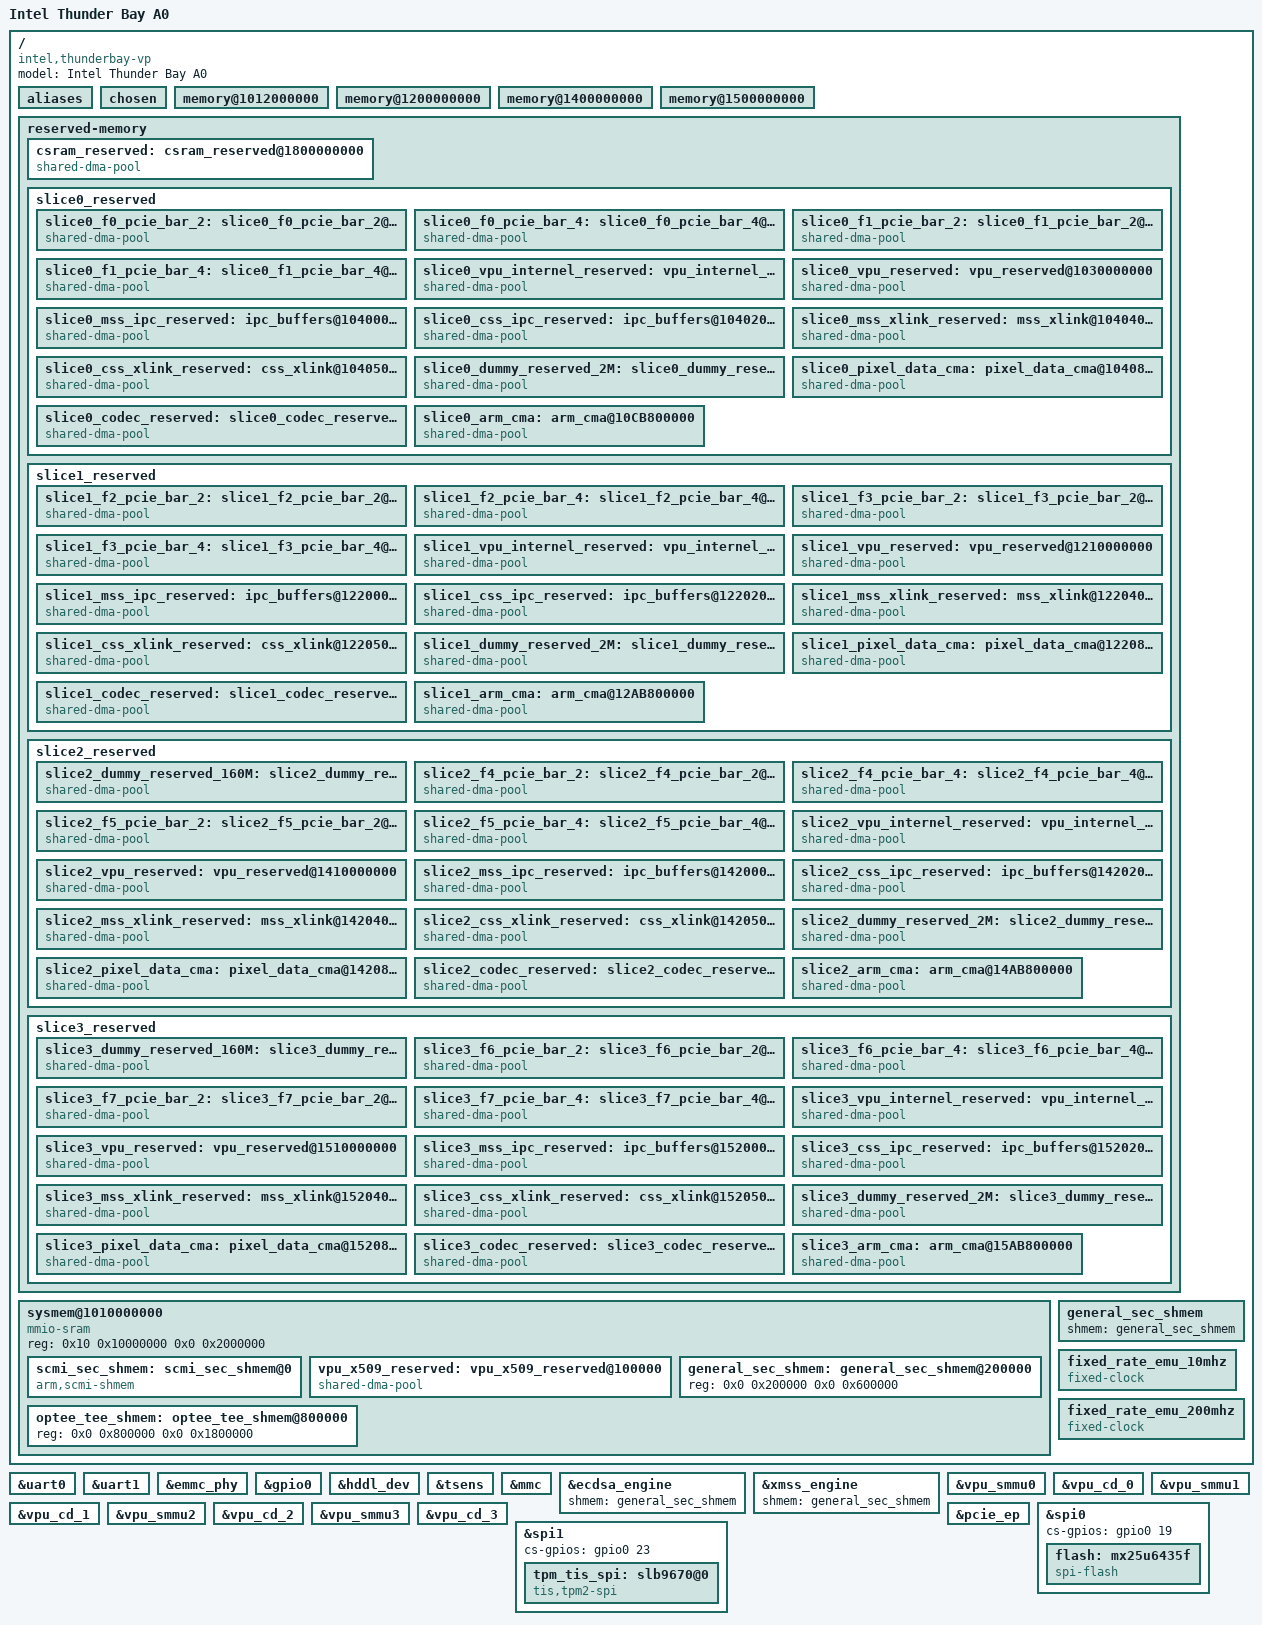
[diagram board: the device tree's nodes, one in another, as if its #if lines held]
/*
 * Device tree describing the Thunder Bay Virtual Platform configuration
 * containing a single Arm core.
 *
 * Copyright (c) 2018 Intel Corporation.
 *
 * SPDX-License-Identifier: GPL-2.0
 *
 */

/dts-v1/;

#include "thb_kernel.dtsi"

/ {
	model = "Intel Thunder Bay A0";
	compatible = "intel,thunderbay-vp";

	#address-cells = <2>;
	#size-cells = <2>;

	aliases {
		serial0 = &uart0;
		serial1 = &uart1;
		spi0 = &spi0;
		spi1 = &spi1;
		gpio0 = &gpio0;
	};

	aliases {
		mmc0 = &mmc;
	};

	chosen {
                //bootargs = "root=/dev/mmcblk0p5 console=uart8250,mmio32,0x80460000,115200n8  initcall_debug rootwait rw rootfstype=ext4";
                bootargs = "mender.data=PARTLABEL=data  root=/dev/mmcblk0p5 console=uart8250,mmio32,0x80460000,115200n8  initcall_debug rootwait rw rootfstype=ext4";
		//bootargs = "root=/dev/mem0      earlycon=uart8250,mmio32,0x80460000,115200n8  initcall_debug rootwait rw rootfstype=ramfs";
		//stdout-path = "serial0:9600n8";
	};

#if ((THB_SLICE_0_EN) || (CRB2_4GB_SLICE_0_SUBMODULE))
	/* 4/8GB of Slice 0 DDR memory */
	memory@1012000000 {
		device_type = "memory";
#if (THB_DDR_CFG_4GB & 0x1)
		reg = <THB_SLICE_0_UPPER32BITS_ADDR 0x12000000 THB_DDR_SLICE0_SIZE_xGB 0xEE000000>;
#else
		reg = <THB_SLICE_0_UPPER32BITS_ADDR 0x12000000 THB_DDR_SLICE0_SIZE_xGB 0xEE000000>;
#endif
	};
#endif

#if ((THB_SLICE_1_EN) || (CRB2_4GB_SLICE_1_SUBMODULE))
	/* 4/8GB of Slice 1 DDR memory */
	memory@1200000000 {
		device_type = "memory";
#if (THB_DDR_CFG_4GB & 0x2)
		reg = <THB_SLICE_1_UPPER32BITS_ADDR SLICE_1_KERNEL_START_ADDR THB_DDR_SLICE1_SIZE_xGB 0x0>;
#else
		reg = <THB_SLICE_1_UPPER32BITS_ADDR SLICE_1_KERNEL_START_ADDR THB_DDR_SLICE1_SIZE_xGB 0x0>;
#endif
	};
#endif

#if (THB_SLICE_2_EN)
	/* 4/8GB of Slice 2 DDR memory */
	memory@1400000000 {
		device_type = "memory";
#if (THB_DDR_CFG_4GB & 0x4)
		reg = <THB_SLICE_2_UPPER32BITS_ADDR 0x0 THB_DDR_SLICE2_SIZE_xGB 0x0>;
#else
		reg = <THB_SLICE_2_UPPER32BITS_ADDR 0x0 THB_DDR_SLICE2_SIZE_xGB 0x0>;
#endif
	};
#endif

#if (THB_SLICE_3_EN)
	/* 4/8GB of Slice 3 DDR memory */
	memory@1500000000 {
		device_type = "memory";
#if (THB_DDR_CFG_4GB & 0x8)
		reg = <THB_SLICE_3_UPPER32BITS_ADDR 0x0 THB_DDR_SLICE3_SIZE_xGB 0x0>;
#else
		reg = <THB_SLICE_3_UPPER32BITS_ADDR 0x0 THB_DDR_SLICE3_SIZE_xGB 0x0>;
#endif
	};
#endif

	reserved-memory {
		#address-cells = <2>;
		#size-cells = <2>;
		ranges;

		csram_reserved: csram_reserved@1800000000 {
			compatible = "shared-dma-pool";
			reg = <0x18 0x00000000 0x0 0x01800000>;
			no-map;
		};

#if (THB_SLICE_0_EN)
		slice0_reserved {
			#address-cells = <2>;
			#size-cells = <2>;
			ranges;

			slice0_f0_pcie_bar_2: slice0_f0_pcie_bar_2@102A000000 {
				compatible = "shared-dma-pool";
				reg = <THB_SLICE_0_UPPER32BITS_ADDR 0x2A000000 0x00 0x1000000>; /* 16MB */
				no-map;
			};

			slice0_f0_pcie_bar_4: slice0_f0_pcie_bar_4@102B000000 {
				compatible = "shared-dma-pool";
				reg = <THB_SLICE_0_UPPER32BITS_ADDR 0x2B000000 0x00 0x800000>; /* 8MB */
				no-map;
			};

			slice0_f1_pcie_bar_2: slice0_f1_pcie_bar_2@102B800000 {
				compatible = "shared-dma-pool";
				reg = <THB_SLICE_0_UPPER32BITS_ADDR 0x2B800000 0x00 0x1000000>; /* 16MB */
				no-map;
			};

			slice0_f1_pcie_bar_4: slice0_f1_pcie_bar_4@102C800000 {
				compatible = "shared-dma-pool";
				reg = <THB_SLICE_0_UPPER32BITS_ADDR 0x2C800000 0x00 0x800000>; /* 8MB */
				no-map;
			};

			/* Reserved for VPU */
			slice0_vpu_internel_reserved: vpu_internel_reserved@102D000000 {
				compatible = "shared-dma-pool";
				reg = <THB_SLICE_0_UPPER32BITS_ADDR 0x2D000000 0x0 0x3000000>; /* 48MB */
				no-map;
			};

			/* Allocate 256MB at fixed location for VPU */
			slice0_vpu_reserved: vpu_reserved@1030000000 {
				compatible = "shared-dma-pool";
				reg = <THB_SLICE_0_UPPER32BITS_ADDR 0x30000000 0x0 0x10000000>; /* 256MB */
				no-map;
			};

			/* Allocate 2MB at fixed location for MSS IPC */
			slice0_mss_ipc_reserved: ipc_buffers@1040000000 {
				compatible = "shared-dma-pool";
				reg = <THB_SLICE_0_UPPER32BITS_ADDR 0x40000000 0x0 0x200000>; /* 2MB */
				no-map;
			};

			/* Allocate 2MB at fixed location for CSS IPC */
			slice0_css_ipc_reserved: ipc_buffers@1040200000 {
				compatible = "shared-dma-pool";
				reg = <THB_SLICE_0_UPPER32BITS_ADDR 0x40200000 0x0 0x200000>; /* 2MB */
				no-map;
			};

			slice0_mss_xlink_reserved: mss_xlink@1040400000 {
				compatible = "shared-dma-pool";
				reg = <THB_SLICE_0_UPPER32BITS_ADDR 0x40400000 0x0 0x00100000>; /* 1MB */
				no-map;
			};

			slice0_css_xlink_reserved: css_xlink@1040500000 {
				compatible = "shared-dma-pool";
				reg = <THB_SLICE_0_UPPER32BITS_ADDR 0x40500000 0x0 0x00100000>; /* 1MB */
				no-map;
			};

			/* Free 2 MB dummy section */
			slice0_dummy_reserved_2M: slice0_dummy_reserved_2M@1040600000 {
				compatible = "shared-dma-pool";
				reg = <THB_SLICE_0_UPPER32BITS_ADDR 0x40600000 0x0 0x200000>; /* 2MB */
				no-map;
			};

			slice0_pixel_data_cma: pixel_data_cma@1040800000 {
				compatible = "shared-dma-pool";
				reg = <THB_SLICE_0_UPPER32BITS_ADDR 0x40800000 0x0 0x6B000000>; /* 1712MB */
				reusable;
			};

			slice0_codec_reserved: slice0_codec_reserved@10AB800000 {
				compatible = "shared-dma-pool";
				reg = <THB_SLICE_0_UPPER32BITS_ADDR 0xAB800000 0x00 0x20000000>; /* 512MB */
				no-map;
			};

			slice0_arm_cma: arm_cma@10CB800000 {
				compatible = "shared-dma-pool";
				reg = <THB_SLICE_0_UPPER32BITS_ADDR 0xCB800000 0x0 0xC000000>; /* 192MB */
				reusable;
			};
		};
#endif

#if (THB_SLICE_1_EN)
		slice1_reserved {
			#address-cells = <2>;
			#size-cells = <2>;
			ranges;
#if (THB_SEC_SLICE)

			slice1_f2_pcie_bar_2: slice1_f2_pcie_bar_2@120A000000 {
				compatible = "shared-dma-pool";
				reg = <THB_SLICE_1_UPPER32BITS_ADDR 0x2A000000 0x00 0x1000000>; /* 16MB */
				no-map;
			};

			slice1_f2_pcie_bar_4: slice1_f2_pcie_bar_4@120B000000 {
				compatible = "shared-dma-pool";
				reg = <THB_SLICE_1_UPPER32BITS_ADDR 0x2B000000 0x00 0x800000>; /* 8MB */
				no-map;
			};

			slice1_f3_pcie_bar_2: slice1_f3_pcie_bar_2@120B800000 {
				compatible = "shared-dma-pool";
				reg = <THB_SLICE_1_UPPER32BITS_ADDR 0x2B800000 0x00 0x1000000>; /* 16MB */
				no-map;
			};

			slice1_f3_pcie_bar_4: slice1_f3_pcie_bar_4@120C800000 {
				compatible = "shared-dma-pool";
				reg = <THB_SLICE_1_UPPER32BITS_ADDR 0x2C800000 0x00 0x800000>; /* 8MB */
				no-map;
			};

			/* Reserved for VPU */
			slice1_vpu_internel_reserved: vpu_internel_reserved@120D000000 {
				compatible = "shared-dma-pool";
				reg = <THB_SLICE_1_UPPER32BITS_ADDR 0x2D000000 0x0 0x3000000>; /* 48MB */
				no-map;
			};

			/* Allocate 256MB at fixed location for VPU */
			slice1_vpu_reserved: vpu_reserved@1210000000 {
				compatible = "shared-dma-pool";
				reg = <THB_SLICE_1_UPPER32BITS_ADDR 0x30000000 0x0 0x10000000>; /* 256MB */
				no-map;
			};

			/* Allocate 2MB at fixed location for MSS IPC */
			slice1_mss_ipc_reserved: ipc_buffers@1220000000 {
				compatible = "shared-dma-pool";
				reg = <THB_SLICE_1_UPPER32BITS_ADDR 0x40000000 0x0 0x200000>; /* 2MB */
				no-map;
			};

			/* Allocate 2MB at fixed location for CSS IPC */
			slice1_css_ipc_reserved: ipc_buffers@1220200000 {
				compatible = "shared-dma-pool";
				reg = <THB_SLICE_1_UPPER32BITS_ADDR 0x40200000 0x0 0x200000>; /* 2MB */
				no-map;
			};

			slice1_mss_xlink_reserved: mss_xlink@1220400000 {
				compatible = "shared-dma-pool";
				reg = <THB_SLICE_1_UPPER32BITS_ADDR 0x40400000 0x0 0x00100000>; /* 1MB */
				no-map;
			};

			slice1_css_xlink_reserved: css_xlink@1220500000 {
				compatible = "shared-dma-pool";
				reg = <THB_SLICE_1_UPPER32BITS_ADDR 0x40500000 0x0 0x00100000>; /* 1MB */
				no-map;
			};

			/* Free 2 MB dummy section */
			slice1_dummy_reserved_2M: slice1_dummy_reserved_2M@1220600000 {
				compatible = "shared-dma-pool";
				reg = <THB_SLICE_1_UPPER32BITS_ADDR 0x40600000 0x0 0x200000>; /* 2MB */
				no-map;
			};

			slice1_pixel_data_cma: pixel_data_cma@1220800000 {
				compatible = "shared-dma-pool";
				reg = <THB_SLICE_1_UPPER32BITS_ADDR 0x40800000 0x0 0x6B000000>; /* 1712MB */
				reusable;
			};

			slice1_codec_reserved: slice1_codec_reserved@128B800000 {
				compatible = "shared-dma-pool";
				reg = <THB_SLICE_1_UPPER32BITS_ADDR 0xAB800000 0x00 0x20000000>; /* 512MB */
				no-map;
			};

			slice1_arm_cma: arm_cma@12AB800000 {
				compatible = "shared-dma-pool";
				reg = <THB_SLICE_1_UPPER32BITS_ADDR 0xCB800000 0x0 0xC000000>; /* 192MB */
				reusable;
			};
#else
			/* Free 160 MB dummy section */
			slice1_dummy_reserved_160M: slice1_dummy_reserved_160M@1200000000 {
				compatible = "shared-dma-pool";
				reg = <THB_SLICE_1_UPPER32BITS_ADDR 0x00000000 0x0 0xA000000>; /* 160MB */
				no-map;
			};

			slice1_f2_pcie_bar_2: slice1_f2_pcie_bar_2@120A000000 {
				compatible = "shared-dma-pool";
				reg = <THB_SLICE_1_UPPER32BITS_ADDR 0x0A000000 0x00 0x1000000>; /* 16MB */
				no-map;
			};

			slice1_f2_pcie_bar_4: slice1_f2_pcie_bar_4@120B000000 {
				compatible = "shared-dma-pool";
				reg = <THB_SLICE_1_UPPER32BITS_ADDR 0x0B000000 0x00 0x800000>; /* 8MB */
				no-map;
			};

			slice1_f3_pcie_bar_2: slice1_f3_pcie_bar_2@120B800000 {
				compatible = "shared-dma-pool";
				reg = <THB_SLICE_1_UPPER32BITS_ADDR 0x0B800000 0x00 0x1000000>; /* 16MB */
				no-map;
			};

			slice1_f3_pcie_bar_4: slice1_f3_pcie_bar_4@120C800000 {
				compatible = "shared-dma-pool";
				reg = <THB_SLICE_1_UPPER32BITS_ADDR 0x0C800000 0x00 0x800000>; /* 8MB */
				no-map;
			};

			/* Reserved for VPU */
			slice1_vpu_internel_reserved: vpu_internel_reserved@120D000000 {
				compatible = "shared-dma-pool";
				reg = <THB_SLICE_1_UPPER32BITS_ADDR 0x0D000000 0x0 0x3000000>; /* 48MB */
				no-map;
			};

			/* Allocate 256MB at fixed location for VPU */
			slice1_vpu_reserved: vpu_reserved@1210000000 {
				compatible = "shared-dma-pool";
				reg = <THB_SLICE_1_UPPER32BITS_ADDR 0x10000000 0x0 0x10000000>; /* 256MB */
				no-map;
			};

			/* Allocate 2MB at fixed location for MSS IPC */
			slice1_mss_ipc_reserved: ipc_buffers@1220000000 {
				compatible = "shared-dma-pool";
				reg = <THB_SLICE_1_UPPER32BITS_ADDR 0x20000000 0x0 0x200000>; /* 2MB */
				no-map;
			};

			/* Allocate 2MB at fixed location for CSS IPC */
			slice1_css_ipc_reserved: ipc_buffers@1220200000 {
				compatible = "shared-dma-pool";
				reg = <THB_SLICE_1_UPPER32BITS_ADDR 0x20200000 0x0 0x200000>; /* 2MB */
				no-map;
			};

			slice1_mss_xlink_reserved: mss_xlink@1220400000 {
				compatible = "shared-dma-pool";
				reg = <THB_SLICE_1_UPPER32BITS_ADDR 0x20400000 0x0 0x00100000>; /* 1MB */
				no-map;
			};

			slice1_css_xlink_reserved: css_xlink@1220500000 {
				compatible = "shared-dma-pool";
				reg = <THB_SLICE_1_UPPER32BITS_ADDR 0x20500000 0x0 0x00100000>; /* 1MB */
				no-map;
			};

			/* Free 2 MB dummy section */
			slice1_dummy_reserved_2M: slice1_dummy_reserved_2M@1220600000 {
				compatible = "shared-dma-pool";
				reg = <THB_SLICE_1_UPPER32BITS_ADDR 0x20600000 0x0 0x00200000>; /* 2MB */
				no-map;
			};

			slice1_pixel_data_cma: pixel_data_cma@1220800000 {
				compatible = "shared-dma-pool";
				reg = <THB_SLICE_1_UPPER32BITS_ADDR 0x20800000 0x0 0x6B000000>; /* 1712MB */
				reusable;
			};

			slice1_codec_reserved: slice1_codec_reserved@128B800000 {
				compatible = "shared-dma-pool";
				reg = <THB_SLICE_1_UPPER32BITS_ADDR 0x8B800000 0x00 0x20000000>; /* 512MB */
				no-map;
			};

			slice1_arm_cma: arm_cma@12AB800000 {
				compatible = "shared-dma-pool";
				reg = <THB_SLICE_1_UPPER32BITS_ADDR 0xAB800000 0x0 0xC000000>; /* 192MB */
				reusable;
			};
#endif
		};
#endif

#if (THB_SLICE_2_EN)
		slice2_reserved {
		#address-cells = <2>;
		#size-cells = <2>;
		ranges;

			/* Free 160 MB dummy section */
			slice2_dummy_reserved_160M: slice2_dummy_reserved_160M@1400000000 {
				compatible = "shared-dma-pool";
				reg = <THB_SLICE_2_UPPER32BITS_ADDR 0x00000000 0x0 0xA000000>; /* 160MB */
				no-map;
			};

			slice2_f4_pcie_bar_2: slice2_f4_pcie_bar_2@140A000000 {
				compatible = "shared-dma-pool";
				reg = <THB_SLICE_2_UPPER32BITS_ADDR 0x0A000000 0x00 0x1000000>; /* 16MB */
				no-map;
			};

			slice2_f4_pcie_bar_4: slice2_f4_pcie_bar_4@140B000000 {
				compatible = "shared-dma-pool";
				reg = <THB_SLICE_2_UPPER32BITS_ADDR 0x0B000000 0x00 0x800000>; /* 8MB */
				no-map;
			};

			slice2_f5_pcie_bar_2: slice2_f5_pcie_bar_2@140B800000 {
				compatible = "shared-dma-pool";
				reg = <THB_SLICE_2_UPPER32BITS_ADDR 0x0B800000 0x00 0x1000000>; /* 16MB */
				no-map;
			};

			slice2_f5_pcie_bar_4: slice2_f5_pcie_bar_4@140C800000 {
				compatible = "shared-dma-pool";
				reg = <THB_SLICE_2_UPPER32BITS_ADDR 0x0C800000 0x00 0x800000>; /* 8MB */
				no-map;
			};

			/* Reserved for VPU */
			slice2_vpu_internel_reserved: vpu_internel_reserved@140D000000 {
				compatible = "shared-dma-pool";
				reg = <THB_SLICE_2_UPPER32BITS_ADDR 0x0D000000 0x0 0x3000000>; /* 48MB */
				no-map;
			};

			/* Allocate 256MB at fixed location for VPU */
			slice2_vpu_reserved: vpu_reserved@1410000000 {
				compatible = "shared-dma-pool";
				reg = <THB_SLICE_2_UPPER32BITS_ADDR 0x10000000 0x0 0x10000000>; /* 256MB */
				no-map;
			};

			/* Allocate 2MB at fixed location for MSS IPC */
			slice2_mss_ipc_reserved: ipc_buffers@1420000000 {
				compatible = "shared-dma-pool";
				reg = <THB_SLICE_2_UPPER32BITS_ADDR 0x20000000 0x0 0x200000>; /* 2MB */
				no-map;
			};

			/* Allocate 2MB at fixed location for CSS IPC */
			slice2_css_ipc_reserved: ipc_buffers@1420200000 {
				compatible = "shared-dma-pool";
				reg = <THB_SLICE_2_UPPER32BITS_ADDR 0x20200000 0x0 0x200000>; /* 2MB */
				no-map;
			};

			slice2_mss_xlink_reserved: mss_xlink@1420400000 {
				compatible = "shared-dma-pool";
				reg = <THB_SLICE_2_UPPER32BITS_ADDR 0x20400000 0x0 0x00100000>; /* 1MB */
				no-map;
			};

			slice2_css_xlink_reserved: css_xlink@1420500000 {
				compatible = "shared-dma-pool";
				reg = <THB_SLICE_2_UPPER32BITS_ADDR 0x20500000 0x0 0x00100000>; /* 1MB */
				no-map;
			};

			/* Free 2 MB dummy section */
			slice2_dummy_reserved_2M: slice2_dummy_reserved_2M@1420600000 {
				compatible = "shared-dma-pool";
				reg = <THB_SLICE_2_UPPER32BITS_ADDR 0x20600000 0x0 0x00200000>; /* 2MB */
				no-map;
			};

			slice2_pixel_data_cma: pixel_data_cma@1420800000 {
				compatible = "shared-dma-pool";
				reg = <THB_SLICE_2_UPPER32BITS_ADDR 0x20800000 0x0 0x6B000000>; /* 1712MB */
				reusable;
			};

			slice2_codec_reserved: slice2_codec_reserved@148B800000 {
				compatible = "shared-dma-pool";
				reg = <THB_SLICE_2_UPPER32BITS_ADDR 0x8B800000 0x00 0x20000000>; /* 512MB */
				no-map;
			};

			slice2_arm_cma: arm_cma@14AB800000 {
				compatible = "shared-dma-pool";
				reg = <THB_SLICE_2_UPPER32BITS_ADDR 0xAB800000 0x0 0xC000000>; /* 192MB */
				reusable;
			};
		};
#endif

#if (THB_SLICE_3_EN)
		slice3_reserved {
			#address-cells = <2>;
			#size-cells = <2>;
			ranges;

			/* Free 160 MB dummy section */
			slice3_dummy_reserved_160M: slice3_dummy_reserved_160M@1500000000 {
				compatible = "shared-dma-pool";
				reg = <THB_SLICE_3_UPPER32BITS_ADDR 0x00000000 0x0 0xA000000>; /* 160MB */
				no-map;
			};

			slice3_f6_pcie_bar_2: slice3_f6_pcie_bar_2@150A000000 {
				compatible = "shared-dma-pool";
				reg = <THB_SLICE_3_UPPER32BITS_ADDR 0x0A000000 0x00 0x1000000>; /* 16MB */
				no-map;
			};

			slice3_f6_pcie_bar_4: slice3_f6_pcie_bar_4@150B000000 {
				compatible = "shared-dma-pool";
				reg = <THB_SLICE_3_UPPER32BITS_ADDR 0x0B000000 0x00 0x800000>; /* 8MB */
				no-map;
			};

			slice3_f7_pcie_bar_2: slice3_f7_pcie_bar_2@150B800000 {
				compatible = "shared-dma-pool";
				reg = <THB_SLICE_3_UPPER32BITS_ADDR 0x0B800000 0x00 0x1000000>; /* 16MB */
				no-map;
			};

			slice3_f7_pcie_bar_4: slice3_f7_pcie_bar_4@150C800000 {
				compatible = "shared-dma-pool";
				reg = <THB_SLICE_3_UPPER32BITS_ADDR 0x0C800000 0x00 0x800000>; /* 8MB */
				no-map;
			};

			/* Reserved for VPU */
			slice3_vpu_internel_reserved: vpu_internel_reserved@150D000000 {
				compatible = "shared-dma-pool";
				reg = <THB_SLICE_3_UPPER32BITS_ADDR 0x0D000000 0x0 0x3000000>; /* 48MB */
				no-map;
			};

			/* Allocate 256MB at fixed location for VPU */
			slice3_vpu_reserved: vpu_reserved@1510000000 {
				compatible = "shared-dma-pool";
				reg = <THB_SLICE_3_UPPER32BITS_ADDR 0x10000000 0x0 0x10000000>; /* 256MB */
				no-map;
			};

			/* Allocate 2MB at fixed location for MSS IPC */
			slice3_mss_ipc_reserved: ipc_buffers@1520000000 {
				compatible = "shared-dma-pool";
				reg = <THB_SLICE_3_UPPER32BITS_ADDR 0x20000000 0x0 0x200000>; /* 2MB */
				no-map;
			};

			/* Allocate 2MB at fixed location for CSS IPC */
			slice3_css_ipc_reserved: ipc_buffers@1520200000 {
				compatible = "shared-dma-pool";
				reg = <THB_SLICE_3_UPPER32BITS_ADDR 0x20200000 0x0 0x200000>; /* 2MB */
				no-map;
			};

			slice3_mss_xlink_reserved: mss_xlink@1520400000 {
				compatible = "shared-dma-pool";
				reg = <THB_SLICE_3_UPPER32BITS_ADDR 0x20400000 0x0 0x00100000>; /* 1MB */
				no-map;
			};

			slice3_css_xlink_reserved: css_xlink@1520500000 {
				compatible = "shared-dma-pool";
				reg = <THB_SLICE_3_UPPER32BITS_ADDR 0x20500000 0x0 0x00100000>; /* 1MB */
				no-map;
			};

			/* Free 2 MB dummy section */
			slice3_dummy_reserved_2M: slice3_dummy_reserved_2M@1520600000 {
				compatible = "shared-dma-pool";
				reg = <THB_SLICE_3_UPPER32BITS_ADDR 0x20600000 0x0 0x00200000>; /* 2MB */
				no-map;
			};

			slice3_pixel_data_cma: pixel_data_cma@1520800000 {
				compatible = "shared-dma-pool";
				reg = <THB_SLICE_3_UPPER32BITS_ADDR 0x20800000 0x0 0x6B000000>; /* 1712MB */
				reusable;
			};

			slice3_codec_reserved: slice3_codec_reserved@158B800000 {
				compatible = "shared-dma-pool";
				reg = <THB_SLICE_3_UPPER32BITS_ADDR 0x8B800000 0x00 0x20000000>; /* 512MB */
				no-map;
			};

			slice3_arm_cma: arm_cma@15AB800000 {
				compatible = "shared-dma-pool";
				reg = <THB_SLICE_3_UPPER32BITS_ADDR 0xAB800000 0x0 0xC000000>; /* 192MB */
				reusable;
			};
		};
#endif
	};

	sysmem@1010000000 {
		compatible = "mmio-sram";
		#address-cells = <2>;
		#size-cells = <2>;
		reg = <0x10 0x10000000 0x0 0x2000000>;
		ranges = <0 0x0  0x10 0x10000000 0x0 0x2000000>;

		/*
		* Allocate 1MB at fixed location for shared memory between
		* non-secure world and BL31 to be used for SCMI.
		*/
		scmi_sec_shmem: scmi_sec_shmem@0 {
			compatible = "arm,scmi-shmem";
			reg = <0x0 0x0 0x0 0x100000>;
			pool;
		};

		/*
		* Allocate some space in shared area for VPU IPC driver
		* to place the X509 certificate.
		*/
		vpu_x509_reserved: vpu_x509_reserved@100000 {
			compatible = "shared-dma-pool";
			reg = <0x0 0x100000 0x0 0x100000>;
			no-map;
		};

		/* Allocate the rest of shared memory for general use.
		 * VPU x509 certificate area will occupy/allocated
		 * from the below region by the IPC driver. So, optee
		 * needs to know the region for the VPU authentication
		 * service TA. https://hsdes.intel.com/resource/16011061170
		 */
		general_sec_shmem: general_sec_shmem@200000 {
			reg = <0x0 0x200000 0x0 0x600000>;
		};

		optee_tee_shmem: optee_tee_shmem@800000 {
                       reg = <0x0 0x800000 0x0 0x1800000>;
               };
	};

	/*
	* For U-Boot to reference the general use shared memory
	* area, we use this node.
	*/
	general_sec_shmem {
		shmem = <&general_sec_shmem>;
	};

	fixed_rate_emu_10mhz: fixed_rate_emu_10mhz {
		compatible = "fixed-clock";
		#clock-cells = <0>;
		clock-frequency = <50000000>;
		clock-output-names = "dummy_clk";
		u-boot,dm-pre-reloc;
	};

	fixed_rate_emu_200mhz: fixed_rate_emu_200mhz {
		compatible = "fixed-clock";
		#clock-cells = <0>;
		clock-frequency = <25000000>;
		clock-output-names = "dummy1_clk";
		u-boot,dm-pre-reloc;
	};
};

&uart0 {
	status = "okay";
};

&uart1 {
	status = "okay";
};

&emmc_phy {
	status = "okay";
	//clocks = <&fixed_rate_emu_200mhz>;
	//clocks = <&scmi_clk PSS_CPR_CPR_CLK>;
};

&gpio0 {
       status = "okay";
};

&hddl_dev {
       status = "okay";
};

&tsens {
       status = "okay";
};

&mmc {
	status = "okay";
	//clocks = <&fixed_rate_emu_200mhz>, <&fixed_rate_emu_200mhz>;
	//clocks = <&scmi_clk EMMC_XIN_CLK>, <&scmi_clk EMMC_AXI_CLK>;
	//assigned-clocks = <&fixed_rate_emu_200mhz>;
	//assigned-clocks = <&scmi_clk EMMC_XIN_CLK>;
};

&ecdsa_engine {
	/* Use general secure-world shared memory. */
	shmem = <&general_sec_shmem>;
};

&xmss_engine {
	/* Use general secure-world shared memory. */
	shmem = <&general_sec_shmem>;
};

#if (THB_SLICE_0_EN)
&vpu_smmu0 {
	status = "okay";
};

&vpu_cd_0 {
	status = "okay";
};
#endif

#if (THB_SLICE_1_EN)
&vpu_smmu1 {
	status = "okay";
};

&vpu_cd_1 {
	status = "okay";
};
#endif

#if (THB_SLICE_2_EN)
&vpu_smmu2 {
	status = "okay";
};

&vpu_cd_2 {
	status = "okay";
};
#endif

#if (THB_SLICE_3_EN)
&vpu_smmu3 {
	status = "okay";
};

&vpu_cd_3 {
	status = "okay";
};
#endif

&pcie_ep {
	status = "okay";
};

&spi0 {
	status = "okay";
	cs-gpios = <&gpio0 19 0>;

	flash: mx25u6435f {
		#address-cells = <1>;
		#size-cells = <1>;
		compatible = "spi-flash";
		spi-max-frequency = <1000000>;
		reg = <0x0>;
		status = "okay";
	};
};

&spi1 {
	status = "okay";
	cs-gpios = <&gpio0 23 0>;
        /* The dTPM will be reset upon platform reset,
         * without additional individual SPI reset control on THB CRB and VV.
         * The CS for VV is enabled in drivers/spi/designware_spi.c.
         * May need to revisit to keep this in DTS for ease of control. CRB doesn't CS.
         */

        tpm_tis_spi: slb9670@0 {
                compatible = "tis,tpm2-spi", "infineon,slb9670";
                spi-max-frequency = <0xA09E6B>;
                reg = <0x0>;
                /* U-Boot will enable fwTPM or dTPM at run-time */
                /*gpio-reset = <&gpio0 49 0>;*/
                status = "okay";
        };
};
